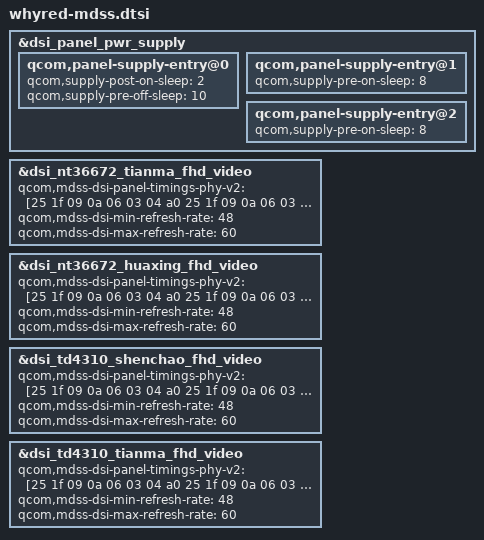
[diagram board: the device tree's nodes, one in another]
#include "dsi-panel-tianma-nt36672-1080p-video.dtsi"
#include "dsi-panel-shenchao-td4310-1080p-video.dtsi"
#include "dsi-panel-tianma-td4310-1080p-video.dtsi"
#include "dsi-panel-huaxing-nt36672-1080p-video.dtsi"

/* sdm660-mdss-panels.dtsi */
&dsi_panel_pwr_supply {
	qcom,panel-supply-entry@0 {
		qcom,supply-post-on-sleep = <2>;
		qcom,supply-pre-off-sleep = <10>;
	};

	qcom,panel-supply-entry@1 {
		qcom,supply-pre-on-sleep = <8>;
	};

	qcom,panel-supply-entry@2 {
		qcom,supply-pre-on-sleep = <8>;
	};
};

&dsi_nt36672_tianma_fhd_video {
	qcom,mdss-dsi-panel-timings-phy-v2 = [25 1f 09 0a 06 03 04 a0
		25 1f 09 0a 06 03 04 a0
		25 1f 09 0a 06 03 04 a0
		25 1f 09 0a 06 03 04 a0
		25 1e 08 0a 06 03 04 a0];
	qcom,mdss-dsi-min-refresh-rate = <48>;
	qcom,mdss-dsi-max-refresh-rate = <60>;
};

 &dsi_nt36672_huaxing_fhd_video {
	qcom,mdss-dsi-panel-timings-phy-v2 = [25 1f 09 0a 06 03 04 a0
		25 1f 09 0a 06 03 04 a0
		25 1f 09 0a 06 03 04 a0
		25 1f 09 0a 06 03 04 a0
		25 1e 08 0a 06 03 04 a0];
	qcom,mdss-dsi-min-refresh-rate = <48>;
	qcom,mdss-dsi-max-refresh-rate = <60>;
};

 &dsi_td4310_shenchao_fhd_video {
	qcom,mdss-dsi-panel-timings-phy-v2 = [25 1f 09 0a 06 03 04 a0
		25 1f 09 0a 06 03 04 a0
		25 1f 09 0a 06 03 04 a0
		25 1f 09 0a 06 03 04 a0
		25 1e 08 0a 06 03 04 a0];
	qcom,mdss-dsi-min-refresh-rate = <48>;
	qcom,mdss-dsi-max-refresh-rate = <60>;
};

 &dsi_td4310_tianma_fhd_video {
	qcom,mdss-dsi-panel-timings-phy-v2 = [25 1f 09 0a 06 03 04 a0
		25 1f 09 0a 06 03 04 a0
		25 1f 09 0a 06 03 04 a0
		25 1f 09 0a 06 03 04 a0
		25 1f 08 0a 06 03 04 a0];
	qcom,mdss-dsi-min-refresh-rate = <48>;
	qcom,mdss-dsi-max-refresh-rate = <60>;
};
